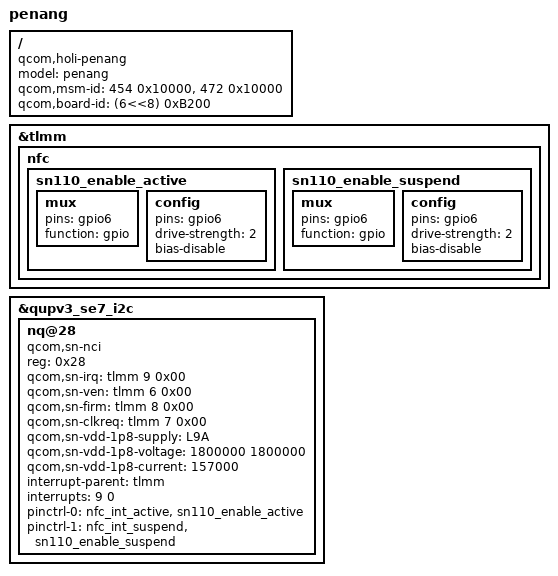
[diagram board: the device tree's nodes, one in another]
/* Copyright (c) 2021, The Linux Foundation. All rights reserved.
 *
 * This program is free software; you can redistribute it and/or modify
 * it under the terms of the GNU General Public License version 2 and
 * only version 2 as published by the Free Software Foundation.
 *
 * This program is distributed in the hope that it will be useful,
 * but WITHOUT ANY WARRANTY; without even the implied warranty of
 * MERCHANTABILITY or FITNESS FOR A PARTICULAR PURPOSE.  See the
 * GNU General Public License for more details.
 */

/dts-v1/;
/plugin/;

#include "holi-penang-common-jp-overlay.dtsi"

/ {
	model = "penang";
	compatible = "qcom,holi-penang", "qcom,holi-moto", "qcom,holi";
	qcom,msm-id = <454 0x10000>, <472 0x10000>;
	qcom,board-id = <(6<<8) 0xB200>;
};

&tlmm {

	nfc {
		sn110_enable_active: sn110_enable_active {
			mux {
				/* 6: Enable, 8: Firmware*/
				pins = "gpio6";
				function = "gpio";
			};

			config {
				pins = "gpio6";
				drive-strength = <2>; /* 2 MA */
				bias-disable;
			};
		};
		sn110_enable_suspend: sn110_enable_suspend {
			mux {
				/* 6: Enable, 8: Firmware */
				pins = "gpio6";
				function = "gpio";
			};

			config {
				pins = "gpio6";
				drive-strength = <2>; /* 2 MA */
				bias-disable;
			};
		};
	};
};

&qupv3_se7_i2c {
	status = "ok";
	#address-cells = <1>;
	#size-cells = <0>;
	nq@28 {
		compatible = "qcom,sn-nci";
		reg = <0x28>;
		qcom,sn-irq = <&tlmm 9 0x00>;
		qcom,sn-ven = <&tlmm 6 0x00>;
		qcom,sn-firm = <&tlmm 8 0x00>;
		qcom,sn-clkreq = <&tlmm 7 0x00>;
		qcom,sn-vdd-1p8-supply = <&L9A>;
		qcom,sn-vdd-1p8-voltage = <1800000 1800000>;
		qcom,sn-vdd-1p8-current = <157000>;
		interrupt-parent = <&tlmm>;
		interrupts = <9 0>;
		interrupt-names = "nfc_irq";
		pinctrl-names = "nfc_active", "nfc_suspend";
		pinctrl-0 = <&nfc_int_active &sn110_enable_active>;
		pinctrl-1 = <&nfc_int_suspend &sn110_enable_suspend>;
	};
};
